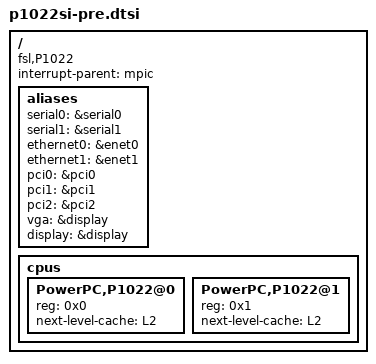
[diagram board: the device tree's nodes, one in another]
/dts-v1/;
/include/ "e500v2_power_isa.dtsi"
/ {
	compatible = "fsl,P1022";
	#address-cells = <2>;
	#size-cells = <2>;
	interrupt-parent = <&mpic>;
	aliases {
		serial0 = &serial0;
		serial1 = &serial1;
		ethernet0 = &enet0;
		ethernet1 = &enet1;
		pci0 = &pci0;
		pci1 = &pci1;
		pci2 = &pci2;
		vga = &display;
		display = &display;
	};
	cpus {
		#address-cells = <1>;
		#size-cells = <0>;
		PowerPC,P1022@0 {
			device_type = "cpu";
			reg = <0x0>;
			next-level-cache = <&L2>;
		};
		PowerPC,P1022@1 {
			device_type = "cpu";
			reg = <0x1>;
			next-level-cache = <&L2>;
		};
	};
};
